# STM32C562 register map
File version: 1.0.0
CPU: CM33 r0p4, little endian, MPU, FPU, 4 interrupt priority bits
Registers are 32-bit, read-write, reset 0x0 unless marked. A register's access mark holds for its fields unless they carry their own. Offsets are from the block's base; [hi:lo] are bit positions; <NAME> marks a mode.

## OPAMP1 — Operational amplifiers
Base 0x40003400
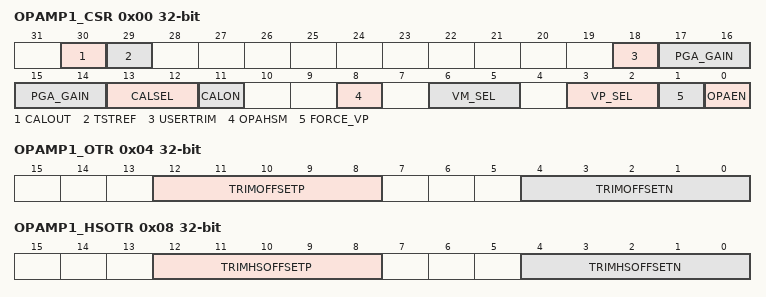
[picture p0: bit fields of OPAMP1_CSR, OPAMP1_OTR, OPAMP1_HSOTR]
0x00 OPAMP1_CSR access per field — OPAMP1 control/status register
  [30] CALOUT ro — Operational amplifier calibration output OPAMP output status flag. During the calibration mode, OPAMP is used as comparator.
    0=Non-inverting < inverting; 1=Non-inverting > inverting
  [29] TSTREF rw — OPAMP calibration reference voltage output control (reserved for test)
    0=INTVREF of OPAMP is not output; 1=INTVREF of OPAMP is output
  [18] USERTRIM rw — User trimming enable This bit allows to switch from factory AOP offset trimmed values to user AOP offset trimmed values This bit is active for both mode normal and high-power.
    0=factory trim code used; 1=user trim code used
  [17:14] PGA_GAIN rw — Operational amplifier Programmable amplifier gain value
    0=Non-inverting internal Gain 2, VREF- referenced; 1=Non-inverting internal Gain 4, VREF- referenced; 2=Non-inverting internal Gain 8, VREF- referenced; 3=Non-inverting internal Gain 16, VREF- referenced; 4=Non-inverting internal Gain 2 with filtering on INM0, VREF- referenced; 5=Non-inverting internal Gain 4 with filtering on INM0, VREF- referenced; 6=Non-inverting internal Gain 8 with filtering on INM0, VREF- referenced; 7=Non-inverting internal Gain 16 with filtering on INM0, VREF- referenced; 8=Inverting gain=-1/ Non-inverting gain =2 with INM0 node for input or bias; 9=Inverting gain=-3/ Non-inverting gain =4 with INM0 node for input or bias; 10=Inverting gain=-7/ Non-inverting gain =8 with INM0 node for input or bias; 11=Inverting gain=-15/ Non-inverting gain =16 with INM0 node for input or bias; 12=Inverting gain=-1/ Non-inverting gain =2 with INM0 node for input or bias, INM1 node for filtering; 13=Inverting gain=-3/ Non-inverting gain =4 with INM0 node for input or bias, INM1 node for filtering; 14=Inverting gain=-7/ Non-inverting gain =8 with INM0 node for input or bias, INM1 node for filtering; 15=Inverting gain=-15/ Non-inverting gain =16 with INM0 node for input or bias, INM1 node for filtering
  [13:12] CALSEL rw — Calibration selection It is used to select the offset calibration bus used to generate the internal reference voltage when CALON = 1 or FORCE_VP= 1.
    0=0.033*VDDA applied on OPAMP inputs; 1=0.1*VDDA applied on OPAMP inputs (for PMOS calibration); 2=0.5*VDDA applied on OPAMP inputs; 3=0.9*VDDA applied on OPAMP inputs (for NMOS calibration)
  [11] CALON rw — Calibration mode enabled
    0=Normal mode; 1=Calibration mode (all switches opened by HW)
  [8] OPAHSM rw — Operational amplifier high-speed mode The operational amplifier must be disable to change this configuration.
    0=operational amplifier in normal mode; 1=operational amplifier in high-speed mode
  [6:5] VM_SEL rw — Inverting input selection
    0=INM0 connected to OPAMP_VINM input; 1=INM1 connected to OPAMP_VINM input; 2=Feedback resistor is connected to OPAMP_VINM input (PGA mode), Inverting input selection is depends on the PGA_GAIN setting; 3=opamp_out connected to OPAMP_VINM input (Follower mode)
  [3:2] VP_SEL rw — Non inverted input selection
    0=GPIO INP0 connected to OPAMP_VINP; 1=dac_out1 connected to OPAMP_VINP; 2=GPIO INP2 is connected to OPAMP_VINP
  [1] FORCE_VP rw — Force internal reference on VP (reserved for test)
    0=Normal operating mode. Non-inverting input connected to inputs.; 1=Calibration verification mode: Non-inverting input connected to calibration reference voltage
  [0] OPAEN rw — Operational amplifier Enable Note: If OPAMP1 is unconnected in a specific package, it must remain disabled (keep OPAMP1_CSR register default value).
    0=operational amplifier disabled; 1=operational amplifier enabled
0x04 OPAMP1_OTR (reset mask 0xFFFF0000) — OPAMP1 trimming register in normal mode
  [12:8] TRIMOFFSETP — Trim for PMOS differential pairs
  [4:0] TRIMOFFSETN — Trim for NMOS differential pairs
0x08 OPAMP1_HSOTR (reset mask 0xFFFF0000) — OPAMP1 trimming register in high-speed mode
  [12:8] TRIMHSOFFSETP — High-speed mode trim for PMOS differential pairs
  [4:0] TRIMHSOFFSETN — High-speed mode trim for NMOS differential pairs
0x0C OPAMP_OR access not given — OPAMP option register
